# PIC32CX5109BZ31032_SL3 register map
Vendor: Microchip Technology; Series: PIC32CXBZ31; File version: 0
CPU: CM4 r0p1, little endian, MPU, FPU, 3 interrupt priority bits, 43 interrupts
Registers are 32-bit, read-write, reset 0x0 unless marked. A register's access mark holds for its fields unless they carry their own. Offsets are from the block's base; [hi:lo] are bit positions.

## RCON
Base 0x44000A00; alternate view of CRU
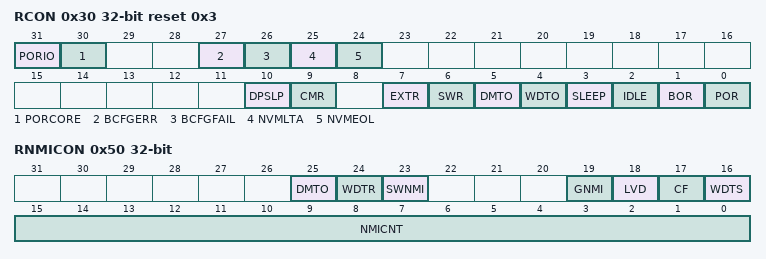
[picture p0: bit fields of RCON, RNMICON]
0x30 RCON reset 0x3 — RESET CONTROL REGISTER
  [31] PORIO — IO Voltage POR Flag bit
    1=PORIO (A Power-up Reset has occurred due to IO Voltage.); 0=NO_PORIO (A Power-up Reset has not occurred due to IO Voltage.)
  [30] PORCORE — Core Voltage POR Flag bit
    1=PORCORE (A Power-up Reset has occurred due to Core Voltage.); 0=NO_PORCORE (A Power-up Reset has not occurred due to Core Voltage.)
  [27] BCFGERR — BCFG Error Flag Bit
    0=NO_BCFGERR (A BCFG Error has not occurred.); 1=BCFGERR (A BCFG Error has occurred.)
  [26] BCFGFAIL — BCFG Failure Flag Bit
    0=NO_BCFGFAIL (A BCFG Failure has not occurred.); 1=BCFGFAIL (A BCFG Failure has occurred.)
  [25] NVMLTA — NVM Life Time Alert Flag Bit
    0=NO_NVMLTA (A NVM LTA Error has not occurred.); 1=NVMLTA (A NVM LTA Error has occurred.)
  [24] NVMEOL — NVM End of Life Flag Bit
    0=NO_NVMEOL (A NVM EOL Failure has not occurred.); 1=NVMEOL (A NVM EOL Failure has occurred.)
  [10] DPSLP — DPSLP Deep Sleep Mode Flag Bit
    1=DSLP (Deep Sleep Mode has occurred.); 0=NOT_DSLP (Deep Sleep Mode has not occurred.)
  [9] CMR — Configuration Mismatch Flag bit
    1=CMR (A Configuration Mismatch Reset Event has occurred.); 0=NOT_CMR (A Configuration Mismatch Reset Event has not occurred.)
  [7] EXTR — External Reset (MCLR) Status bit
    1=EXTR (A Master Clear (pin) Reset has occurred.); 0=NOT_EXTR (A Master Clear (pin) Reset has not occurred.)
  [6] SWR — Software Reset Flag bit
    1=SWR (A Software Commanded Reset has occurred.); 0=NOT_SWR (A Software Commanded Reset has not occurred.)
  [5] DMTO — Deadman Timer Time-Out Flag bit
    1=DMTO (DMT Time-out has occurred and caused a reset.); 0=NOT_DMTO (DMT Time-out has not occurred.)
  [4] WDTO — Watchdog Timer Time-Out Flag bit
    1=WDTO (WDT Time-out has occurred and caused a reset.); 0=NOT_WDTO (WDT Time-out has not occurred.)
  [3] SLEEP — Wake from Sleep Flag bit
    1=SLEEP (Device has been in Sleep mode.); 0=NOT_SLEEP (Device has not been in Sleep mode.)
  [2] IDLE — Wake from Idle Flag bit
    1=IDLE (Device was in Idle mode.); 0=NOT_IDLE (Device was not in Idle mode.)
  [1] BOR — Brown-out Reset Flag bit
    1=BOR (A Brown-out Reset has occurred.); 0=NO_BOR (A Brown-out Reset has not occurred.)
  [0] POR — Power-On Reset Flag bit
    1=POR (A Power-up Reset has occurred.); 0=NO_POR (A Power-up Reset has not occurred.)
0x34 RCONCLR
0x38 RCONSET
0x3C RCONINV
0x40 RSWRST wo — SOFTWARE RESET REGISTER
  [0] SWRST — Software Reset Trigger
    1=SWRST (Enable software reset event); 0=NO_SWRST (Do not enable software reset event)
0x44 RSWRSTCLR
0x48 RSWRSTSET
0x4C RSWRSTINV
0x50 RNMICON — NMI CONTROL REGISTER
  [25] DMTO — Deadman Timer Time-Out Flag bit
    1=DMTO (DMT Time-out has occurred and caused a NMI.); 0=NO_DMTO (DMT Time-out has not occurred.)
  [24] WDTR — Watchdog Timer Time-Out in Run Flag bit
    1=WDTR (WDT Time-out has occurred and caused a NMI.); 0=NO_WDTR (WDT Time-out has not occurred.)
  [23] SWNMI — Software NMI Trigger
    1=SWNMI (Writing a 1 to this bit will cause an NMI to be generated); 0=NO_SWNMI (Writing a 0 to this bit will have no effect.)
  [19] GNMI — External / Generic NMI Event
    1=NMI (A general NMI event has been detected and caused an NMI); 0=NO_NMI (A general NMI event has not been detected.)
  [18] LVD — Programmable Low Voltage Detect Event
    1=LVD (PLVD has detected a low voltage condition and caused an NMI); 0=NO_LVD (PLVD has not detected a low voltage condition)
  [17] CF — Clock Fail Detect bit
    1=CFAIL (FSCM has detected clock failure and caused an NMI); 0=NO_FAILDET (FSCM has not detected clock failure)
  [16] WDTS — Watch-Dog Timer Time-Out in Sleep Flag bit
    1=WDTS (WDT Time-out has occurred during sleep_mode and caused a wake-up from sleep.); 0=NO_WDTS (WDT Time-out has not occurred during sleep_mode.)
  [15:0] NMICNT — NMI Reset counter value
    0=NODLY (No delay between NMI assertion and device reset event); 1=1CLKDLY (1 sys_clk cycle that Software has to clear the NMI event before a device reset is performed.); 2=2CLKDLY (2 sys_clk cycles that Software has to clear the NMI event before a device reset is performed.); 0xFFFF=64KCLKDLY (65535 sys_clk cycles that Software has to clear the NMI event before a device reset is performed.)
0x54 RNMICONCLR
0x58 RNMICONSET
0x5C RNMICONINV

## Notices in the file
Copyright (c) 2026 Microchip Technology Inc.
SPDX-License-Identifier: Apache-2.0
Licensed under the Apache License, Version 2.0 (the "License");
you may not use this file except in compliance with the License.
You may obtain a copy of the License at
http://www.apache.org/licenses/LICENSE-2.0
Unless required by applicable law or agreed to in writing, software
distributed under the License is distributed on an "AS IS" BASIS,
WITHOUT WARRANTIES OR CONDITIONS OF ANY KIND, either express or implied.
See the License for the specific language governing permissions and
limitations under the License.
